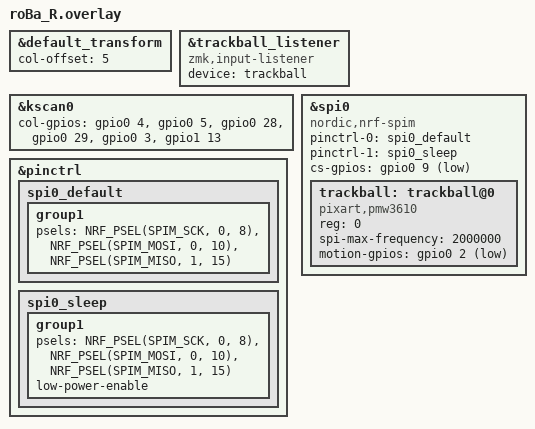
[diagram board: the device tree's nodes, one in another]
/*
 * Copyright (c) 2024 The ZMK Contributors
 *
 * SPDX-License-Identifier: MIT
 */

#include <dt-bindings/zmk/matrix_transform.h>
#include <dt-bindings/zmk/keys.h>
#include <dt-bindings/zmk/bt.h>
#include <dt-bindings/zmk/outputs.h>
#include <dt-bindings/zmk/pointing.h>

#include "roBa.dtsi"

&default_transform {
    col-offset = <5>;
};

&trackball_listener {
    status = "okay";
    compatible = "zmk,input-listener";
    device = <&trackball>;
};

&kscan0 {
    col-gpios =
        <&gpio0  4 GPIO_ACTIVE_HIGH>,
        <&gpio0  5 GPIO_ACTIVE_HIGH>,
        <&gpio0 28 GPIO_ACTIVE_HIGH>,
        <&gpio0 29 GPIO_ACTIVE_HIGH>,
        <&gpio0  3 GPIO_ACTIVE_HIGH>,
        <&gpio1 13 GPIO_ACTIVE_HIGH>;
};

&pinctrl {
    spi0_default: spi0_default {
        group1 {
            psels = <NRF_PSEL(SPIM_SCK, 0, 8)>,
                    <NRF_PSEL(SPIM_MOSI, 0, 10)>,
                    <NRF_PSEL(SPIM_MISO, 1, 15)>;
        };
    };

    spi0_sleep: spi0_sleep {
        group1 {
            psels = <NRF_PSEL(SPIM_SCK, 0, 8)>,
                    <NRF_PSEL(SPIM_MOSI, 0, 10)>,
                    <NRF_PSEL(SPIM_MISO, 1, 15)>;
            low-power-enable;
        };
    };
};

&spi0 {
    status = "okay";
    compatible = "nordic,nrf-spim";
    pinctrl-0 = <&spi0_default>;
    pinctrl-1 = <&spi0_sleep>;
    pinctrl-names = "default", "sleep";
    cs-gpios = <&gpio0 9 GPIO_ACTIVE_LOW>;

    trackball: trackball@0 {
        status = "okay";
        compatible = "pixart,pmw3610";
        reg = <0>;
        spi-max-frequency = <2000000>;
        motion-gpios = <&gpio0 2 (GPIO_ACTIVE_LOW | GPIO_PULL_UP)>;
    };
};
